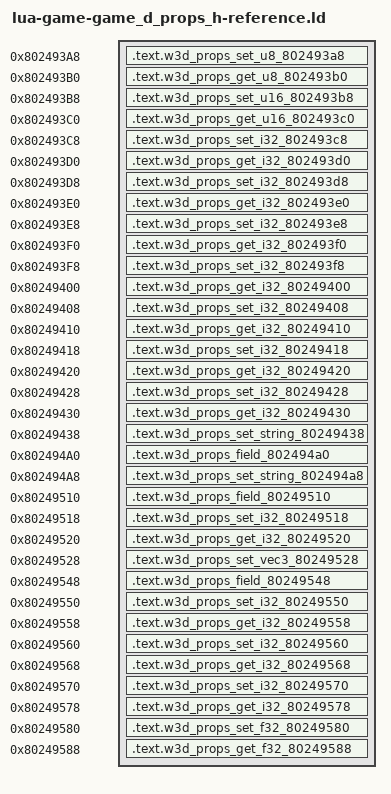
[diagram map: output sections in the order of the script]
/* Generated reference-only placements. All bodies are source-built. */
OUTPUT_FORMAT("elf32-powerpc")
OUTPUT_ARCH(powerpc)
ENTRY(w3d_props_set_u8_802493a8)
_SDA_BASE_ = 0x804b2540;
_SDA2_BASE_ = 0x804c2540;
w3d_string_release_header = 0x8020bb2c;
SECTIONS {
  .text.w3d_props_set_u8_802493a8 0x802493a8 : { *(.text.w3d_props_set_u8_802493a8) }
  .text.w3d_props_get_u8_802493b0 0x802493b0 : { *(.text.w3d_props_get_u8_802493b0) }
  .text.w3d_props_set_u16_802493b8 0x802493b8 : { *(.text.w3d_props_set_u16_802493b8) }
  .text.w3d_props_get_u16_802493c0 0x802493c0 : { *(.text.w3d_props_get_u16_802493c0) }
  .text.w3d_props_set_i32_802493c8 0x802493c8 : { *(.text.w3d_props_set_i32_802493c8) }
  .text.w3d_props_get_i32_802493d0 0x802493d0 : { *(.text.w3d_props_get_i32_802493d0) }
  .text.w3d_props_set_i32_802493d8 0x802493d8 : { *(.text.w3d_props_set_i32_802493d8) }
  .text.w3d_props_get_i32_802493e0 0x802493e0 : { *(.text.w3d_props_get_i32_802493e0) }
  .text.w3d_props_set_i32_802493e8 0x802493e8 : { *(.text.w3d_props_set_i32_802493e8) }
  .text.w3d_props_get_i32_802493f0 0x802493f0 : { *(.text.w3d_props_get_i32_802493f0) }
  .text.w3d_props_set_i32_802493f8 0x802493f8 : { *(.text.w3d_props_set_i32_802493f8) }
  .text.w3d_props_get_i32_80249400 0x80249400 : { *(.text.w3d_props_get_i32_80249400) }
  .text.w3d_props_set_i32_80249408 0x80249408 : { *(.text.w3d_props_set_i32_80249408) }
  .text.w3d_props_get_i32_80249410 0x80249410 : { *(.text.w3d_props_get_i32_80249410) }
  .text.w3d_props_set_i32_80249418 0x80249418 : { *(.text.w3d_props_set_i32_80249418) }
  .text.w3d_props_get_i32_80249420 0x80249420 : { *(.text.w3d_props_get_i32_80249420) }
  .text.w3d_props_set_i32_80249428 0x80249428 : { *(.text.w3d_props_set_i32_80249428) }
  .text.w3d_props_get_i32_80249430 0x80249430 : { *(.text.w3d_props_get_i32_80249430) }
  .text.w3d_props_set_string_80249438 0x80249438 : { *(.text.w3d_props_set_string_80249438) }
  .text.w3d_props_field_802494a0 0x802494a0 : { *(.text.w3d_props_field_802494a0) }
  .text.w3d_props_set_string_802494a8 0x802494a8 : { *(.text.w3d_props_set_string_802494a8) }
  .text.w3d_props_field_80249510 0x80249510 : { *(.text.w3d_props_field_80249510) }
  .text.w3d_props_set_i32_80249518 0x80249518 : { *(.text.w3d_props_set_i32_80249518) }
  .text.w3d_props_get_i32_80249520 0x80249520 : { *(.text.w3d_props_get_i32_80249520) }
  .text.w3d_props_set_vec3_80249528 0x80249528 : { *(.text.w3d_props_set_vec3_80249528) }
  .text.w3d_props_field_80249548 0x80249548 : { *(.text.w3d_props_field_80249548) }
  .text.w3d_props_set_i32_80249550 0x80249550 : { *(.text.w3d_props_set_i32_80249550) }
  .text.w3d_props_get_i32_80249558 0x80249558 : { *(.text.w3d_props_get_i32_80249558) }
  .text.w3d_props_set_i32_80249560 0x80249560 : { *(.text.w3d_props_set_i32_80249560) }
  .text.w3d_props_get_i32_80249568 0x80249568 : { *(.text.w3d_props_get_i32_80249568) }
  .text.w3d_props_set_i32_80249570 0x80249570 : { *(.text.w3d_props_set_i32_80249570) }
  .text.w3d_props_get_i32_80249578 0x80249578 : { *(.text.w3d_props_get_i32_80249578) }
  .text.w3d_props_set_f32_80249580 0x80249580 : { *(.text.w3d_props_set_f32_80249580) }
  .text.w3d_props_get_f32_80249588 0x80249588 : { *(.text.w3d_props_get_f32_80249588) }
  /DISCARD/ : { *(.text*) *(.rodata*) *(.data*) *(.bss*) *(.sdata*) *(.sbss*) *(.comment) }
}
